# DSS1_COMMON1 register map
Vendor: Texas Instruments
Peripheral module from a debugger description file (folder am62P).
Registers are 32-bit, access not given, reset 0x0 unless marked. A register's access mark holds for its fields unless they carry their own. Offsets are as the file gives them; lines under a group give offsets from that group; [hi:lo] are bit positions; {n}, {i} and the like mark numbered series; 'fields as' and 'values as' point back to an identical list; <NAME> marks a mode.

## DSS1_COMMON1
0x24 COMMON1_DISPC_IRQ_EOI access per field — End Of Interrupt number
  [0] EOI wo — Software End Of Interrupt [EOI] control if pulse interrupts are used. Write 1 to acknowledge interrupt
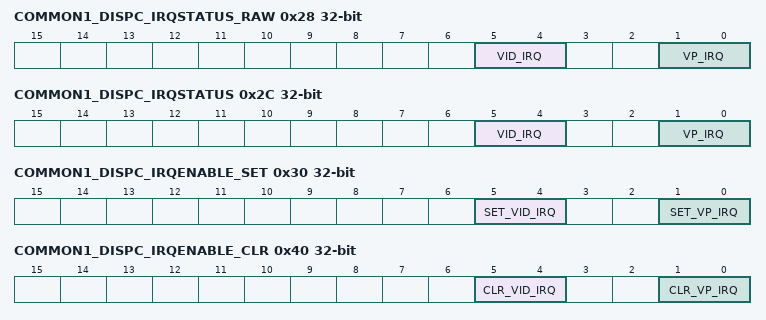
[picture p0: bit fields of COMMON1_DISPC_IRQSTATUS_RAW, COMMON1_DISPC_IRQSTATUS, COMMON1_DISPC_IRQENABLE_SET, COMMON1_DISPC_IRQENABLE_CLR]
0x28 COMMON1_DISPC_IRQSTATUS_RAW — RAW Interrupt status. Raw status is set even if interrupt is not enabled. Write 1 to set the RAW status
  [5:4] VID_IRQ — VID IRQ STATUS. Register indicates the VIDEO pipeline[s] interrupt events (access R/W1TS)
  [1:0] VP_IRQ — VP IRQ STATUS. Register indicates the Video Port[s] interrupt events (access R/W1TS)
0x2C COMMON1_DISPC_IRQSTATUS — Interrupt status. Enabled status, isn't set unless event is enabled. Write 1 to clear the status after interrupt has been serviced. RAW status also gets cleared, i.e. even if not enabled
  [5:4] VID_IRQ — VID IRQ STATUS. Register indicates the VIDEO pipeline[s] interrupt events (access R/W1TC)
  [1:0] VP_IRQ — VP IRQ STATUS. Register indicates the Video Port[s] interrupt events (access R/W1TC)
0x30 COMMON1_DISPC_IRQENABLE_SET — SET Interrupt enable. Write 1 to set interrupt enable. Readout equal to corresponding _CLR register
  [5:4] SET_VID_IRQ — VID IRQ (access R/W1TS)
  [1:0] SET_VP_IRQ — VP IRQ (access R/W1TS)
0x40 COMMON1_DISPC_IRQENABLE_CLR — CLR Interrupt enable. Write 1 to clear interrupt enable
  [5:4] CLR_VID_IRQ — VID IRQ (access R/W1TC)
  [1:0] CLR_VP_IRQ — VP IRQ (access R/W1TC)
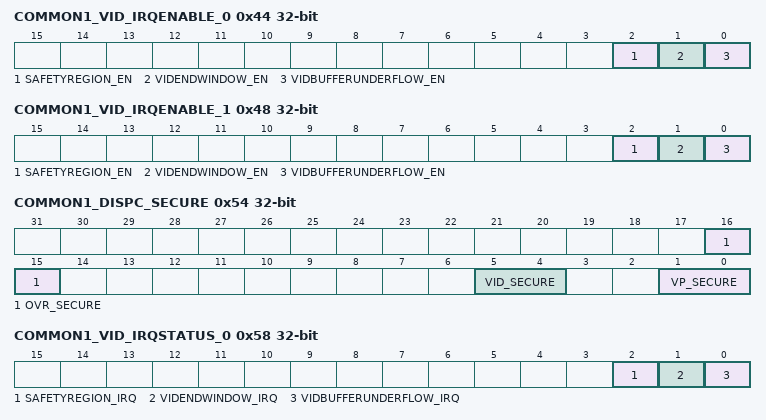
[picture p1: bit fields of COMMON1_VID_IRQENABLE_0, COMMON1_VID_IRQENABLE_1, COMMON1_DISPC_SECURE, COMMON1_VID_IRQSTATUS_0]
0x44 COMMON1_VID_IRQENABLE_0 rw — This register allows to mask/unmask the VID_0 internal sources of interrupt, on an event-by-event basis
  [2] SAFETYREGION_EN — Safety Feature IRQ. This is raised when FrameFreeze is detected or data mismatch occurs within the safety region
  [1] VIDENDWINDOW_EN — Video End Window. This is raised by the DMA engine when the full video data has been sent to the pipeline
  [0] VIDBUFFERUNDERFLOW_EN — Video DMA Buffer Underflow. This is raised when the DMA buffer does not have the data requested by the Video pipeline
0x48 COMMON1_VID_IRQENABLE_1 rw — This register allows to mask/unmask the VIDL_0 internal sources of interrupt, on an event-by-event basis
  fields as COMMON1_VID_IRQENABLE_0
0x54 COMMON1_DISPC_SECURE rw — Security bit settings for different DISPC sub-modules
  [16:15] OVR_SECURE — Secure bit for OVR
  [5:4] VID_SECURE — Secure bit for VID
  [1:0] VP_SECURE — Secure bit for VP [Unused in K3_DSS]
0x58 COMMON1_VID_IRQSTATUS_0 — This register groups all the status of the VID_0 internal events that generate an interrupt. Write 1 to a clear a bit field
  [2] SAFETYREGION_IRQ — Safety Feature IRQ. This is raised when FrameFreeze is detected or data mismatch occurs within the safety region (access R/W1TC)
  [1] VIDENDWINDOW_IRQ — Video End Window. This is raised by the DMA engine when the full video data has been sent to the pipeline (access R/W1TC)
  [0] VIDBUFFERUNDERFLOW_IRQ — Video DMA Buffer Underflow. This is raised when the DMA buffer does not have the data requested by the Video pipeline (access R/W1TC)
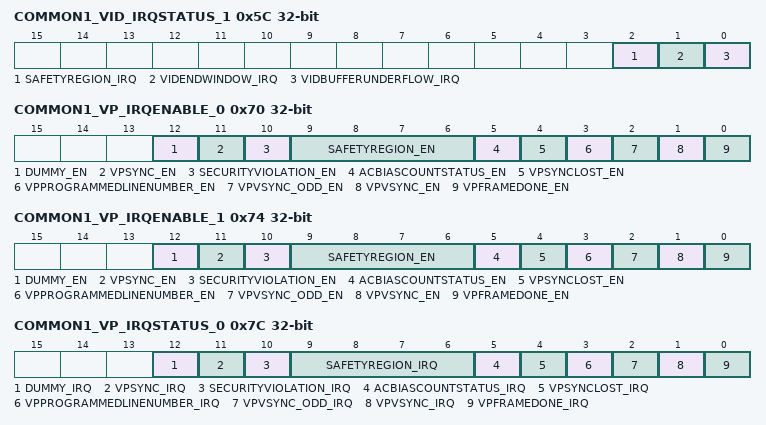
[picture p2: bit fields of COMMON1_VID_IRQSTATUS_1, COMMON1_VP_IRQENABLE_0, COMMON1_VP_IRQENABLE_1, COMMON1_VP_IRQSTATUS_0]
0x5C COMMON1_VID_IRQSTATUS_1 — This register groups all the status of the VID_0 internal events that generate an interrupt. Write 1 to a clear a bit field
  fields as COMMON1_VID_IRQSTATUS_0
0x70 COMMON1_VP_IRQENABLE_0 rw — This register allows to mask/unmask the VP_0 internal sources of interrupt, on an event-by-event basis
  [12] DUMMY_EN — Dummy IRQ for future use
  [11] VPSYNC_EN — Go bit clear event
  [10] SECURITYVIOLATION_EN — Security Violation interrupt for OVR/VP. Non-secure OVR/VP connected to secure VID
  [9:6] SAFETYREGION_EN — Safety Feature IRQ. This is raised when FrameFreeze is detected or data mismatch occurs within the safety region
  [5] ACBIASCOUNTSTATUS_EN — AC BIAS transition counter has decremented to zero
  [4] VPSYNCLOST_EN — Synchronization Lost for Video Port
  [3] VPPROGRAMMEDLINENUMBER_EN — Programmed Line Number. It indicates that the scan of the display has reached the programmed user line number
  [2] VPVSYNC_ODD_EN — VSYNC for odd field from interlace mode only
  [1] VPVSYNC_EN — Vertical Synchronization for VP
  [0] VPFRAMEDONE_EN — Frame Done for Video Port. VP output has been disabled by user. All the data have been sent
0x74 COMMON1_VP_IRQENABLE_1 rw — This register allows to mask/unmask the VP_1 internal sources of interrupt, on an event-by-event basis
  fields as COMMON1_VP_IRQENABLE_0
0x7C COMMON1_VP_IRQSTATUS_0 — This register groups all the status of the VP_0 internal events that generate an interrupt. Write 1 to a given bit resets this bit
  [12] DUMMY_IRQ — Dummy IRQ for future use (access R/W1TC)
  [11] VPSYNC_IRQ — Go bit clear event (access R/W1TC)
  [10] SECURITYVIOLATION_IRQ — Security Violation IRQ. Non-secure OVR/VP connected to secure VID (access R/W1TC)
  [9:6] SAFETYREGION_IRQ — Safety Feature IRQ. This is raised when FrameFreeze is detected or data mismatch occurs within the safety region (access R/W1TC)
  [5] ACBIASCOUNTSTATUS_IRQ — AC BIAS transition counter has decremented to zero (access R/W1TC)
  [4] VPSYNCLOST_IRQ — Synchronization Lost on VP output. The required data are not output at the correct time due to too short blanking periods or stall of at least one pipelines associated with VP output (access R/W1TC)
  [3] VPPROGRAMMEDLINENUMBER_IRQ — Programmed Line Number. It indicates that the scan of the display has reached the programmed user line number (access R/W1TC)
  [2] VPVSYNC_ODD_IRQ — VSYNC for odd field. For interlace mode only (access R/W1TC)
  [1] VPVSYNC_IRQ — Vertical Synchronization for VP output. It is used as VSYNC_EVEN in case of interlace mode (access R/W1TC)
  [0] VPFRAMEDONE_IRQ — Frame Done for VP. VP output has been disabled by user All the data have been sent (access R/W1TC)
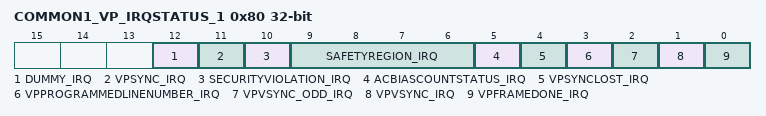
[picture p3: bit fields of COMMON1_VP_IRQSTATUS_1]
0x80 COMMON1_VP_IRQSTATUS_1 — This register groups all the status of the VP_1 internal events that generate an interrupt. Write 1 to a given bit resets this bit
  fields as COMMON1_VP_IRQSTATUS_0
